# ATmega2564RFR2 device description
Architecture: AVR8; Family: megaAVR
Registers are 8-bit, access not given, no defined reset value unless marked. A register's access mark holds for its fields unless they carry their own. Offsets are from the block's base; [hi:lo] are bit positions.

## TWI — Two Wire Serial Interface
Instances: TWI 0x00
0xB8 TWBR — TWI Bit Rate Register
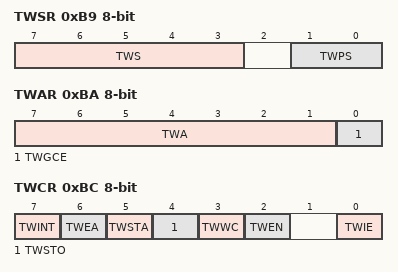
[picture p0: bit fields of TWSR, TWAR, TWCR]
0xB9 TWSR — TWI Status Register
  [7:3] TWS (bit 3 of the value upward) — TWI Status
    0=Bus error due to illegal START or STOP condition; 8=A START condition has been transmitted; 16=A repeated START condition has been transmitted; 24=SLA+W has been transmitted; ACK has been received; 32=SLA+W has been transmitted; NOT ACK has been received; 40=Data byte has been transmitted; ACK has been received; 48=Data byte has been transmitted; NOT ACK has been received; 56=Arbitration lost in SLA+W or data bytes (Transmitter); Arbitration lost in SLA+R or NOT ACK bit (Receiver); 64=SLA+R has been transmitted; ACK has been received; 72=SLA+R has been transmitted; NOT ACK has been received; 80=Data byte has been received; ACK has been returned; 88=Data byte has been received; NOT ACK has been returned; 96=Own SLA+W has been received; ACK has been returned; 104=Arbitration lost in SLA+R/W as Master; own SLA+W has been received; ACK has been returned; 112=General call address has been received; ACK has been returned; 120=Arbitration lost in SLA+R/W as Master; general call address has been received; ACK has been returned; 128=Previously addressed with own SLA+W; data has been received; ACK has been returned; 136=Previously addressed with own SLA+W; data has been received; NOT ACK has been returned; 144=Previously addressed with general call; data has been received; ACK has been returned; 152=Previously addressed with general call; data has been received; NOT ACK has been returned; 160=A STOP condition or repeated START condition has been received while still addressed as Slave; 168=Own SLA+R has been received; ACK has been returned; 176=Arbitration lost in SLA+R/W as Master; own SLA+R has been received; ACK has been returned; 184=Data byte in TWDR has been transmitted; ACK has been received; 192=Data byte in TWDR has been transmitted; NO ACK has been received; 200=Last data byte in TWDR has been transmitted (TWEA = 0); ACK has been received; 248=No relevant state information available; TWINT = 0
  [1:0] TWPS — TWI Prescaler Bits
    0=1; 1=4; 2=16; 3=64
0xBA TWAR — TWI (Slave) Address Register
  [7:1] TWA — TWI (Slave) Address
  [0] TWGCE — TWI General Call Recognition Enable Bit
0xBB TWDR — TWI Data Register
0xBC TWCR — TWI Control Register
  [7] TWINT — TWI Interrupt Flag
  [6] TWEA — TWI Enable Acknowledge Bit
  [5] TWSTA — TWI START Condition Bit
  [4] TWSTO — TWI STOP Condition Bit
  [3] TWWC — TWI Write Collision Flag
  [2] TWEN — TWI Enable Bit
  [0] TWIE — TWI Interrupt Enable
0xBD TWAMR — TWI (Slave) Address Mask Register
  [7:1] TWAM — TWI Address Mask

## SPI — Serial Peripheral Interface
Instances: SPI 0x00
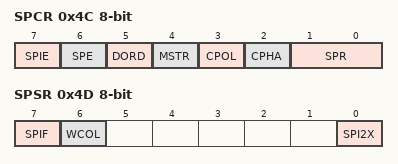
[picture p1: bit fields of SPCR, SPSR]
0x4C SPCR — SPI Control Register
  [7] SPIE — SPI Interrupt Enable
  [6] SPE — SPI Enable
  [5] DORD — Data Order
  [4] MSTR — Master/Slave Select
  [3] CPOL — Clock polarity
    0=Rising (Leading Edge), Falling (Trailing Edge); 1=Falling (Leading Egde), Rising (Trailing Edge)
  [2] CPHA — Clock Phase
    0=Sample (Leading Edge), Setup (Trailing Edge); 1=Setup (Leading Edge), Sample (Trailing Edge)
  [1:0] SPR — SPI Clock Rate Select 1 and 0
    0=fosc/4 / fosc/2 (SPI2X=0/1); 1=fosc/16 / fosc/8 (SPI2X=0/1); 2=fosc/64 / fosc/32 (SPI2X=0/1); 3=fosc/128 / fosc/64 (SPI2X=0/1)
0x4D SPSR — SPI Status Register
  [7] SPIF — SPI Interrupt Flag
  [6] WCOL — Write Collision Flag
  [0] SPI2X — Double SPI Speed Bit
0x4E SPDR — SPI Data Register

## USART0_SPI — Serial Peripheral Interface
Instances: USART0_SPI 0x00
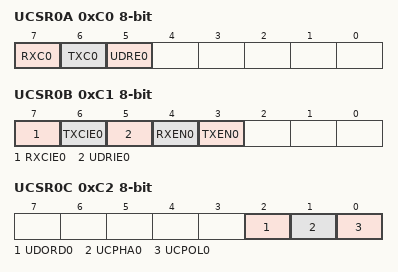
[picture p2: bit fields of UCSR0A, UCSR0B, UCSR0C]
0xC0 UCSR0A — USART0 MSPIM Control and Status Register A
  [7] RXC0 — USART Receive Complete
  [6] TXC0 — USART Transmit Complete
  [5] UDRE0 — USART Data Register Empty
0xC1 UCSR0B — USART0 MSPIM Control and Status Register B
  [7] RXCIE0 — RX Complete Interrupt Enable
  [6] TXCIE0 — TX Complete Interrupt Enable
  [5] UDRIE0 — USART Data Register Empty Interrupt Enable
  [4] RXEN0 — Receiver Enable
  [3] TXEN0 — Transmitter Enable
0xC2 UCSR0C — USART0 MSPIM Control and Status Register C
  [2] UDORD0 — Data Order
  [1] UCPHA0 — Clock Phase
  [0] UCPOL0 — Clock Polarity
